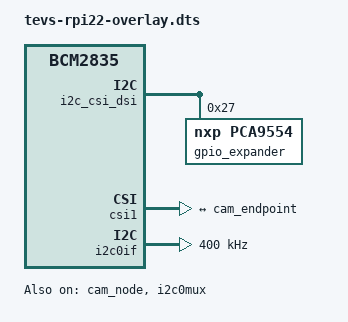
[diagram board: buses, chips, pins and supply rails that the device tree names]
// SPDX-License-Identifier: GPL-2.0-only
// Definitions for TEVS camera module on VC I2C bus
/dts-v1/;
/plugin/;

#include <dt-bindings/gpio/gpio.h>

/{
	compatible = "brcm,bcm2835";

	i2c_frag: fragment@0 {
		target = <&i2c_csi_dsi>;
		__overlay__ {
			#address-cells = <1>;
			#size-cells = <0>;
			status = "okay";

			gpio_expander: pca9554@27 {
				compatible = "nxp,pca9554";
				reg = <0x27>;
				gpio-controller;
				#gpio-cells = <2>;
				gpio-line-names = "EXPOSURE_TRIG_IN1", 
								  "FLASH_OUT1", 
								  "CAM_SHUTTER1", 
								  "XVS1",
								  "CSI1_PDB", 
								  "CSI1_INT", 
								  "INFO_TRIG_IN1", 
								  "CSI1_RST_N";
				status = "okay";
			};

			#include "tevs.dtsi"
		};
	};

	csi_frag: fragment@1 {
		target = <&csi1>;
		csi: __overlay__ {
			status = "okay";
			brcm,media-controller;

			port {
				csi_ep: endpoint {
					remote-endpoint = <&cam_endpoint>;
					clock-lanes = <0>;
					data-lanes = <1 2 3 4>;
					clock-noncontinuous;
				};
			};
		};
	};

	fragment@2 {
		target = <&i2c0if>;
		__overlay__ {
			status = "okay";
			clock-frequency = <400000>;
		};
	};

	clk_frag: fragment@3 {
		target = <&cam1_clk>;
		__overlay__ {
			status = "okay";
			clock-frequency = <24000000>;
		};
	};

	fragment@4 {
		target = <&i2c0mux>;
		__overlay__ {
			status = "okay";
		};
	};

	__overrides__ {
		rotation = <&cam_node>,"rotation:0";
		orientation = <&cam_node>,"orientation:0";
		media-controller = <&csi>,"brcm,media-controller?";
		cam0 = <&i2c_frag>, "target:0=",<&i2c_csi_dsi1>,
		       <&csi_frag>, "target:0=",<&csi1>,
		       <&clk_frag>, "target:0=",<&cam0_clk>,
		       <&cam_node>, "clocks:0=",<&cam0_clk>,
		       <&cam_node>, "VANA-supply:0=",<&cam0_reg>;
	};
};

&cam_node {
	status = "okay";
};

&cam_endpoint {
	remote-endpoint = <&csi_ep>;
};
